# PIC32CZ8110CA80100 register map
Vendor: Microchip Technology; Series: PIC32CZCA80; File version: 0
CPU: CM7 r1p1, little endian, MPU, FPU, double-precision FPU, I-cache, D-cache, ITCM, DTCM, 3 interrupt priority bits, 222 interrupts
Registers are 32-bit, read-write, reset 0x0 unless marked. A register's access mark holds for its fields unless they carry their own. Offsets are from the block's base; [hi:lo] are bit positions; 'fields as' and 'values as' point back to an identical list.

## DRMTCM — DRM TCM ECC
Base 0x44820000
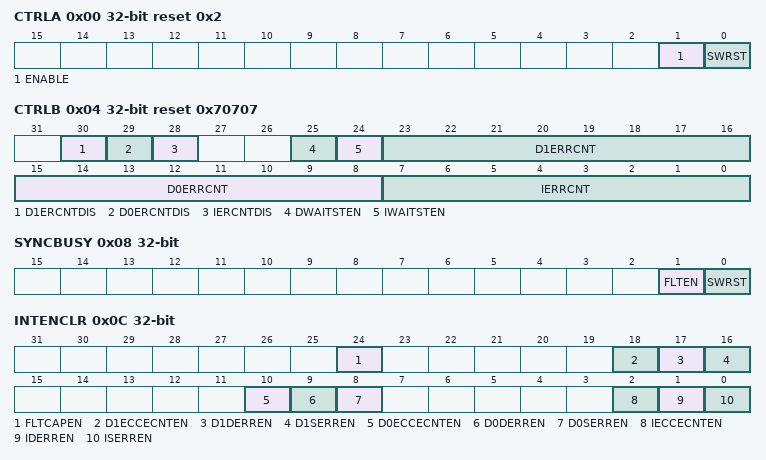
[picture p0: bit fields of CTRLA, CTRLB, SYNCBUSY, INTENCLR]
0x00 CTRLA reset 0x2 — CONTROL ENABLE REGISTER A
  [1] ENABLE — DRMTCM ECC Enable (ON) bit (default ECC is always enabled)
  [0] SWRST — DRMTCM Software Reset
0x04 CTRLB reset 0x70707 — CONTROL ENABLE REGISTER B
  [30] D1ERCNTDIS — D1TCM ERROR COUNTER DISABLE BIT
  [29] D0ERCNTDIS — D0TCM ERROR COUNTER DISABLE BIT
  [28] IERCNTDIS — ITCM ERROR COUNTER DISABLE BIT
  [25] DWAITSTEN — D1TCM and D0TCM ONE WAIT STATE ENABLE BIT
  [24] IWAITSTEN — ITCM ONE WAIT STATE ENABLE BIT
  [23:16] D1ERRCNT — D1TCM ERROR MAXIMUM COUNT (default 0x7)
  [15:8] D0ERRCNT — D0TCM ERROR MAXIMUM COUNT (default 0x7)
  [7:0] IERRCNT — ITCM ERROR MAXIMUM COUNT (default 0x7)
0x08 SYNCBUSY ro
  [1] FLTEN — Fault Injection Enabled busy bit --- Synchronizing Busy bit for FLTEN register (when hard-ware set this bit, no writes are allowed to the FLTCTRL register until after the synchronizing is not busy).
  [0] SWRST — Software reset busy bit --- Synchronizing Busy bit for SWRST
0x0C INTENCLR write-1-clears — INTERRUPT ENABLE CLR REGISTER
  [24] FLTCAPEN — Fault Capture interrupt enable bit Disable
  [18] D1ECCECNTEN — D1TCM ECC Error Count Flag bit Disable
  [17] D1DERREN — D1TCM Double Bit Error Detection Flag bit Disable
  [16] D1SERREN — D1TCM Single Bit Error Detection Flag bit Disable
  [10] D0ECCECNTEN — D0TCM ECC Error Count Flag bit Disable
  [9] D0DERREN — D0TCM Double Bit Error Detection Flag bit Disable
  [8] D0SERREN — D0TCM Single Bit Error Detection Flag bit Disable
  [2] IECCECNTEN — ITCM ECC Error Count Flag bit Disable
  [1] IDERREN — ITCM Double Bit Error Detection Flag bit Disable
  [0] ISERREN — ITCM Single Bit Error Detection Flag bit Disable
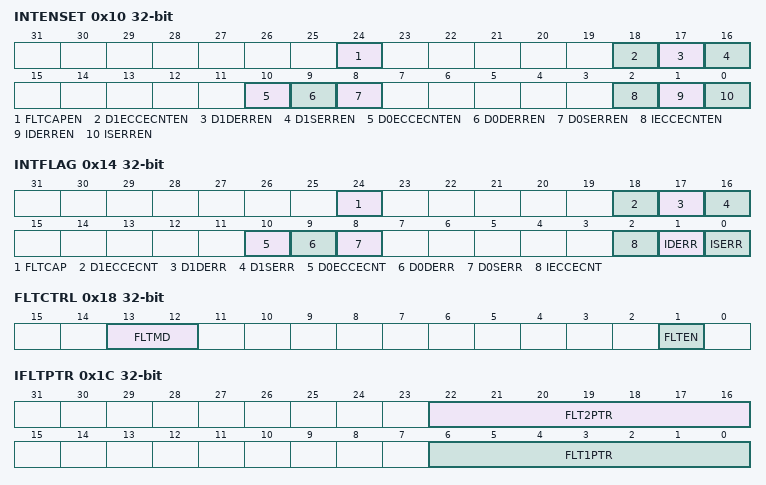
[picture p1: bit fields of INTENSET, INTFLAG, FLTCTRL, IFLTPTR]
0x10 INTENSET write-1-sets — INTERRUPT ENABLE SET REGISTER
  [24] FLTCAPEN — Fault Capture interrupt enable bit Enable
  [18] D1ECCECNTEN — D1TCM ECC Error Count Flag bit Enable
  [17] D1DERREN — D1TCM Double Bit Error Detection Flag bit Enable
  [16] D1SERREN — D1TCM Single Bit Error Detection Flag bit Enable
  [10] D0ECCECNTEN — D0TCM ECC Error Count Flag bit Enable
  [9] D0DERREN — D0TCM Double Bit Error Detection Flag bit Enable
  [8] D0SERREN — D0TCM Single Bit Error Detection Flag bit Enable
  [2] IECCECNTEN — ITCM ECC Error Count Flag bit Enable
  [1] IDERREN — ITCM Double Bit Error Detection Flag bit Enable
  [0] ISERREN — ITCM Single Bit Error Detection Flag bit Enable
0x14 INTFLAG write-1-clears — INTERRUPT FLAG REGISTER
  [24] FLTCAP — Fault Capture interrupt
  [18] D1ECCECNT — D1TCM ECC Error Count Flag
  [17] D1DERR — D1TCM Double Bit Error Detection Flag
  [16] D1SERR — D1TCM Single Bit Error Detection Flag
  [10] D0ECCECNT — D0TCM ECC Error Count Flag
  [9] D0DERR — D0TCM Double Bit Error Detection Flag
  [8] D0SERR — D0TCM Single Bit Error Detection Flag
  [2] IECCECNT — ITCM ECC Error Count Flag
  [1] IDERR — ITCM Double Bit Error Detection Flag
  [0] ISERR — ITCM Single Bit Error Detection Flag
0x18 FLTCTRL — FAULT INJECTION CONTROL REGISTER
  [13:12] FLTMD — Fault Mode Control
  [1] FLTEN — Fault Injection Enabled
0x1C IFLTPTR — ITCM FAULT INJECTION POINTER REGISTER
  [22:16] FLT2PTR — ECC Fault injection Bit position pointer (for double bit error).
  [6:0] FLT1PTR — ECC Fault injection Bit position pointer (for single bit error).
0x20 IFLTADR — ITCM FAULT INJECTION ADDRESS REGISTER
  [16:0] IFLTADR — Instruction ITCM ECC Fault Injection, Address Match Com-pare bits.
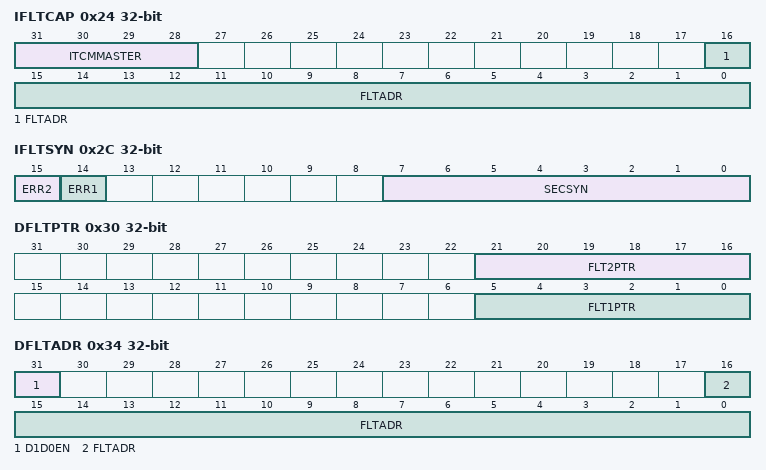
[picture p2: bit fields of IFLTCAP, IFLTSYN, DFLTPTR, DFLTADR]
0x24 IFLTCAP ro — ITCM FAULT ERROR CAPTURE ADDRESS REGISTER
  [31:28] ITCMMASTER — Master ID of the requester of the current Error access.
  [16:0] FLTADR — Instruction TCM ECC Fault Address bits which caused the ECC Error.
0x28 IFLTPAR ro — ITCM FAULT PARITY REGISTER
  [7:0] SECIN — Single Error Parity Bits from ITCM
0x2C IFLTSYN ro — ITCM FAULT ECC SYNDROME REGISTER
  [15] ERR2 — Double bit Error
  [14] ERR1 — Single Bit Error
  [7:0] SECSYN — Single Error Syndrome
0x30 DFLTPTR — DTCM FAULT INJECTION POINTER REGISTER
  [21:16] FLT2PTR — ECC Fault injection Bit position pointer (for double bit error).
  [5:0] FLT1PTR — ECC Fault injection Bit position pointer (for single bit error).
0x34 DFLTADR — DTCM FAULT INJECTION ADDRESS REGISTER
  [31] D1D0EN — Fault Injection D1 or D0 Address Enable.
  [16:0] FLTADR — Data TCM ECC Fault Injection, Address Match Compare bits.
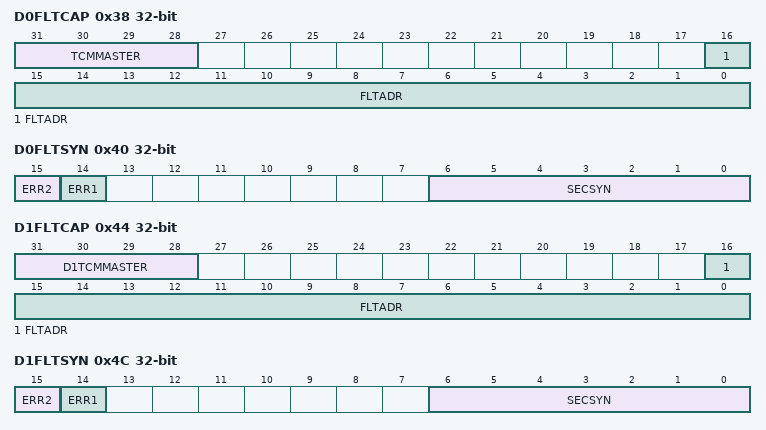
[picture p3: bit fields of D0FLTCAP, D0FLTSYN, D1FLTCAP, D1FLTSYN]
0x38 D0FLTCAP ro — D0TCM FAULT ERROR CAPTURE ADDRESS REGISTER
  [31:28] TCMMASTER — Master ID of the requester of the current Error access.
  [16:0] FLTADR — Data 0 TCM ECC Fault Address bits which caused the ECC Error.
0x3C D0FLTPAR ro — D0TCM FAULT PARITY REGISTER
  [6:0] SECIN — Single Error Parity Bits from D0TCM
0x40 D0FLTSYN ro — D0TCM FAULT ECC SYNDROME REGISTER
  [15] ERR2 — Double bit Error
  [14] ERR1 — Single Bit Error
  [6:0] SECSYN — Single Error Syndrome
0x44 D1FLTCAP ro — D1TCM FAULT ERROR CAPTURE ADDRESS REGISTER
  [31:28] D1TCMMASTER — Master ID of the requester of the current Error access.
  [16:0] FLTADR — Data 1 TCM ECC Fault Address bits which caused the ECC Error.
0x48 D1FLTPAR ro — D1TCM FAULT PARITY REGISTER
  [6:0] SECIN — Single Error Parity Bits from D1TCM
0x4C D1FLTSYN ro — D1TCM FAULT ECC SYNDROME REGISTER
  fields as D0FLTSYN

## Notices in the file
Copyright (c) 2026 Microchip Technology Inc.
SPDX-License-Identifier: Apache-2.0
Licensed under the Apache License, Version 2.0 (the "License");
you may not use this file except in compliance with the License.
You may obtain a copy of the License at
http://www.apache.org/licenses/LICENSE-2.0
Unless required by applicable law or agreed to in writing, software
distributed under the License is distributed on an "AS IS" BASIS,
WITHOUT WARRANTIES OR CONDITIONS OF ANY KIND, either express or implied.
See the License for the specific language governing permissions and
limitations under the License.
